# DPHY_TX0 register map
Vendor: Texas Instruments
Registers are 32-bit, read-write, reset 0x0 unless marked. A register's access mark holds for its fields unless they carry their own. Offsets are as the file gives them; [hi:lo] are bit positions; {n}, {i} and the like mark numbered series; <NAME> marks a mode.

## DPHY_TX0 (part 2 of 2)
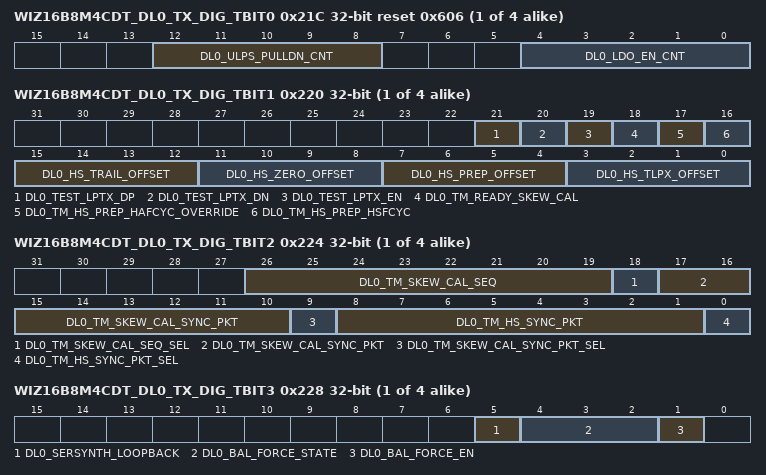
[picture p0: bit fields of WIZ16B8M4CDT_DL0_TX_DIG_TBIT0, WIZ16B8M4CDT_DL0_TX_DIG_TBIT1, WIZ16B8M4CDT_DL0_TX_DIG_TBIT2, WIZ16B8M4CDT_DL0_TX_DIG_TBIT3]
{0x21C+0x100*i} WIZ16B8M4CDT_DL{i}_TX_DIG_TBIT0 reset 0x606 (i=0..3)
  [12:8] DL{i}_ULPS_PULLDN_CNT — After enabling LDO, ulps_pulldn will go to 0 after these many uS
  [4:0] DL{i}_LDO_EN_CNT — Once the analog's power down signal is de asserted, LDO will be enabled after these many uS
{0x220+0x100*i} WIZ16B8M4CDT_DL{i}_TX_DIG_TBIT1 (i=0..3)
  [21] DL{i}_TEST_LPTX_DP — send 0 to LP TX Dn in HS mode
  [20] DL{i}_TEST_LPTX_DN — send 0 to LP TX Dp in HS mode
  [19] DL{i}_TEST_LPTX_EN — give output for LPTX from dig logic for HS entry LP sequence
  [18] DL{i}_TM_READY_SKEW_CAL — Assert o_TxReadyHS during skew caliberation pattern transmission.
  [17] DL{i}_TM_HS_PREP_HAFCYC_OVERRIDE — HS Prepare extra half cycle offset is controlled by digital logic
  [16] DL{i}_TM_HS_PREP_HSFCYC — If bit 17 == 1 Sets HS Prepare extra offset to 0 half cycle
  [15:12] DL{i}_HS_TRAIL_OFFSET — Sets HS-TRAIL Offset to 0
  [11:8] DL{i}_HS_ZERO_OFFSET — Sets HS-ZERO offset to 0
  [7:4] DL{i}_HS_PREP_OFFSET — Sets HS-PREPARE offset to 0
  [3:0] DL{i}_HS_TLPX_OFFSET — Sets TLPX Offset to 0
{0x224+0x100*i} WIZ16B8M4CDT_DL{i}_TX_DIG_TBIT2 (i=0..3)
  [26:19] DL{i}_TM_SKEW_CAL_SEQ — desired skew calibration test sequence
  [18] DL{i}_TM_SKEW_CAL_SEQ_SEL — To send 'AA as skew calibration pattern
  [17:10] DL{i}_TM_SKEW_CAL_SYNC_PKT — desired skew calibration test sync packet
  [9] DL{i}_TM_SKEW_CAL_SYNC_PKT_SEL — To send 'FF as Skew calibration sync packet
  [8:1] DL{i}_TM_HS_SYNC_PKT — desired HS test sync packet
  [0] DL{i}_TM_HS_SYNC_PKT_SEL — To send 'B8 as HS sync packet
{0x228+0x100*i} WIZ16B8M4CDT_DL{i}_TX_DIG_TBIT3 (i=0..3)
  [5] DL{i}_SERSYNTH_LOOPBACK — De-serialiser will take input from sampler
  [4:2] DL{i}_BAL_FORCE_STATE — Force the SYNC packet detection logic into below states if <1> is '1', SYNC_DONE state
  [1] DL{i}_BAL_FORCE_EN — SYNC packet detection FSM in serialiser in BIST mode will work as per logic
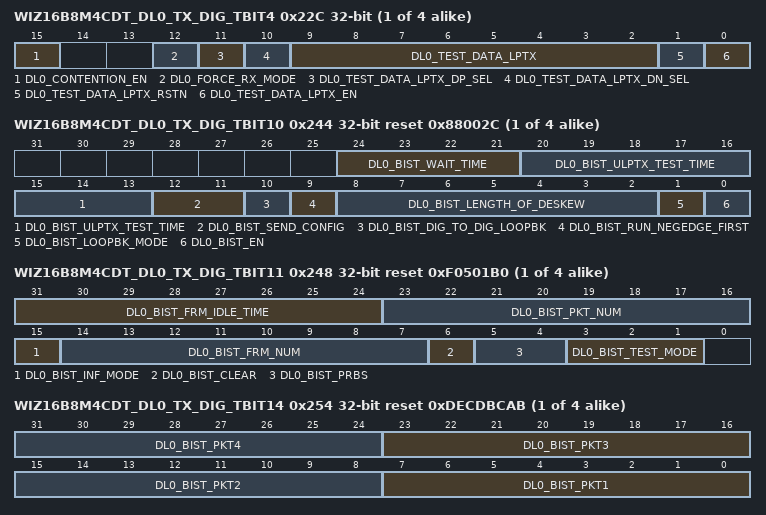
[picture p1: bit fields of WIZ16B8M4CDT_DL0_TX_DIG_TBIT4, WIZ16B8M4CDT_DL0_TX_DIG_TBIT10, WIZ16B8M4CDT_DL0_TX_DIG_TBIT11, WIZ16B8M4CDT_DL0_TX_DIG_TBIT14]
{0x22C+0x100*i} WIZ16B8M4CDT_DL{i}_TX_DIG_TBIT4 (i=0..3)
  [15] DL{i}_CONTENTION_EN — Contention detector logic is enabled
  [12] DL{i}_FORCE_RX_MODE — Force LPRX into RX mode
  [11] DL{i}_TEST_DATA_LPTX_DP_SEL — Normal_ LPTX DP_B from logic for LPDT
  [10] DL{i}_TEST_DATA_LPTX_DN_SEL — Normal_ LPTX DN_B from logic for LPDT
  [9:2] DL{i}_TEST_DATA_LPTX — LPTX test data
  [1] DL{i}_TEST_DATA_LPTX_RSTN — LP test data logic is RESET
  [0] DL{i}_TEST_DATA_LPTX_EN — LP test data logic DISABLED
{0x230+0x100*i} WIZ16B8M4CDT_DL{i}_TX_DIG_TBIT5 access not given reset not defined (i=0..3)
{0x234+0x100*i} WIZ16B8M4CDT_DL{i}_TX_DIG_TBIT6 access not given reset not defined (i=0..3)
{0x238+0x100*i} WIZ16B8M4CDT_DL{i}_TX_DIG_TBIT7 access not given reset not defined (i=0..3)
{0x23C+0x100*i} WIZ16B8M4CDT_DL{i}_TX_DIG_TBIT8 access not given reset not defined (i=0..3)
{0x240+0x100*i} WIZ16B8M4CDT_DL{i}_TX_DIG_TBIT9 access not given reset not defined (i=0..3)
{0x244+0x100*i} WIZ16B8M4CDT_DL{i}_TX_DIG_TBIT10 reset 0x88002C (i=0..3)
  [24:21] DL{i}_BIST_WAIT_TIME — BIST wait time between posedge run and negedge run of sampler clock
  [20:13] DL{i}_BIST_ULPTX_TEST_TIME — While testing ULPTX, LP00 will be maintained on DPDN for this many number of byte clock cycles
  [12:11] DL{i}_BIST_SEND_CONFIG — Option of configuring what to send in BIST mose. To send both deskew and HS data
  [10] DL{i}_BIST_DIG_TO_DIG_LOOPBK — main digital to pattern checker loopback enabled
  [9] DL{i}_BIST_RUN_NEGEDGE_FIRST — BIST will run with posedge of sampler clock first
  [8:2] DL{i}_BIST_LENGTH_OF_DESKEW — Length of deskew sequence In terms of us. By default 13us of deskew sequence will be transmitted
  [1] DL{i}_BIST_LOOPBK_MODE — loopback_mode bit, EXTERNAL_LOOPBACK
  [0] DL{i}_BIST_EN — BIST Disabled
{0x248+0x100*i} WIZ16B8M4CDT_DL{i}_TX_DIG_TBIT11 reset 0xF0501B0 (i=0..3)
  [31:24] DL{i}_BIST_FRM_IDLE_TIME — BIST_FRM_IDLE time is time between the frames
  [23:16] DL{i}_BIST_PKT_NUM — BIST_PAK_NUM is number of packets that are to be transmitted per frame
  [15] DL{i}_BIST_INF_MODE — run infinite BIST mode
  [14:7] DL{i}_BIST_FRM_NUM — BIST_FRM_NUM is number of frames to be transmitted
  [6] DL{i}_BIST_CLEAR — clear the bist
  [5:4] DL{i}_BIST_PRBS — BIST PRBS MODE 9
  [3:1] DL{i}_BIST_TEST_MODE — PRBS mode
{0x24C+0x100*i} WIZ16B8M4CDT_DL{i}_TX_DIG_TBIT12 reset 0x28 (i=0..3)
  [11:0] DL{i}_BIST_RUN_LENGTH — BIST_RUN_LENGTH
{0x250+0x100*i} WIZ16B8M4CDT_DL{i}_TX_DIG_TBIT13 reset 0xA (i=0..3)
  [7:0] DL{i}_BIST_IDLE_TIME — BIST_IDLE_TIME
{0x254+0x100*i} WIZ16B8M4CDT_DL{i}_TX_DIG_TBIT14 reset 0xDECDBCAB (i=0..3)
  [8n-1:8n-8] DL{i}_BIST_PKT{n} (n=1..4) — BIST_TEST_PAT{n}
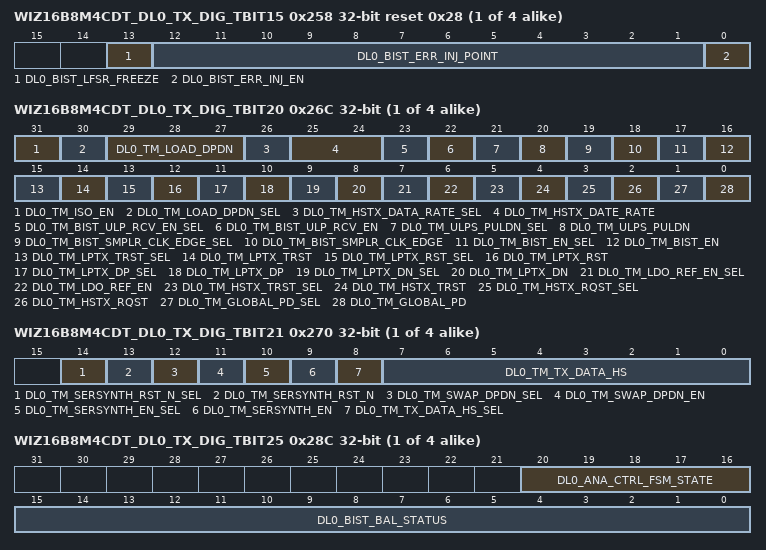
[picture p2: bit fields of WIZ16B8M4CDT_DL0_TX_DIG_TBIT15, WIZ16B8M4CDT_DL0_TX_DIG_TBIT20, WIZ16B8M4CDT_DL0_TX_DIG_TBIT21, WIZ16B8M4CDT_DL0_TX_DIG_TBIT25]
{0x258+0x100*i} WIZ16B8M4CDT_DL{i}_TX_DIG_TBIT15 reset 0x28 (i=0..3)
  [13] DL{i}_BIST_LFSR_FREEZE — Reset LFSR contents after every packet or frame
  [12:1] DL{i}_BIST_ERR_INJ_POINT — BIST_ERR_INJECT_POINT is where to inject the error in the packet
  [0] DL{i}_BIST_ERR_INJ_EN — Inject error in the BIST during the packet
{0x25C+0x100*i} WIZ16B8M4CDT_DL{i}_TX_DIG_TBIT16 access not given reset not defined (i=0..3)
{0x260+0x100*i} WIZ16B8M4CDT_DL{i}_TX_DIG_TBIT17 access not given reset not defined (i=0..3)
{0x264+0x100*i} WIZ16B8M4CDT_DL{i}_TX_DIG_TBIT18 access not given reset not defined (i=0..3)
{0x268+0x100*i} WIZ16B8M4CDT_DL{i}_TX_DIG_TBIT19 access not given reset not defined (i=0..3)
{0x26C+0x100*i} WIZ16B8M4CDT_DL{i}_TX_DIG_TBIT20 (i=0..3)
  [31] DL{i}_TM_ISO_EN — Enable isolation in test mode
  [30] DL{i}_TM_LOAD_DPDN_SEL — Take ana_dpdn_load from dig logic
  [29:27] DL{i}_TM_LOAD_DPDN — set ana_dpdn_load as per requirement in test mode
  [26] DL{i}_TM_HSTX_DATA_RATE_SEL — Take ana_hstx_datarate from dig logic
  [25:24] DL{i}_TM_HSTX_DATE_RATE — set ana_hstx_datarate as per requirement in test mode
  [23] DL{i}_TM_BIST_ULP_RCV_EN_SEL — Take ana_bist_ulps_rcv_en from dig logic
  [22] DL{i}_TM_BIST_ULP_RCV_EN — set ana_bist_ulps_rcv_en to 0
  [21] DL{i}_TM_ULPS_PULDN_SEL — Take ana_ulps_puldn from dig logic
  [20] DL{i}_TM_ULPS_PULDN — set ana_ulps_puldn to 0
  [19] DL{i}_TM_BIST_SMPLR_CLK_EDGE_SEL — Take ana_bist_smplr_clkedge from dig logic
  [18] DL{i}_TM_BIST_SMPLR_CLK_EDGE — set ana_bist_smplr_clkedge to posedge
  [17] DL{i}_TM_BIST_EN_SEL — Take ana_bist_en from dig logic
  [16] DL{i}_TM_BIST_EN — set ana_bist_en to 0
  [15] DL{i}_TM_LPTX_TRST_SEL — Take ana_lptx_trst from dig logic
  [14] DL{i}_TM_LPTX_TRST — set ana_lptx_trst to 0
  [13] DL{i}_TM_LPTX_RST_SEL — Take ana_lptx_rst from dig logic
  [12] DL{i}_TM_LPTX_RST — set ana_lptx_rst to 0
  [11] DL{i}_TM_LPTX_DP_SEL — give output for LPTX DP from dig logic
  [10] DL{i}_TM_LPTX_DP — send 0 to LP TX Dp
  [9] DL{i}_TM_LPTX_DN_SEL — give output for LPTX DN from dig logic
  [8] DL{i}_TM_LPTX_DN — send 0 to LP TX Dn
  [7] DL{i}_TM_LDO_REF_EN_SEL — Take ana_ldo_ref_en from dig logic
  [6] DL{i}_TM_LDO_REF_EN — set ana_ldo_ref_en to 0
  [5] DL{i}_TM_HSTX_TRST_SEL — Take ana_hstx_trst from dig logic
  [4] DL{i}_TM_HSTX_TRST — set ana_hstx_trst to 0
  [3] DL{i}_TM_HSTX_RQST_SEL — Take ana_hstx_rqst from dig logic
  [2] DL{i}_TM_HSTX_RQST — set ana_hstx_rqst to 0
  [1] DL{i}_TM_GLOBAL_PD_SEL — Take ana_global_pd from dig logic
  [0] DL{i}_TM_GLOBAL_PD — set ana_global_pd to 0 (powered up)
{0x270+0x100*i} WIZ16B8M4CDT_DL{i}_TX_DIG_TBIT21 (i=0..3)
  [14] DL{i}_TM_SERSYNTH_RST_N_SEL — Take sersynth_rst_n from dig logic
  [13] DL{i}_TM_SERSYNTH_RST_N — Set sersynth_rst_n to 1
  [12] DL{i}_TM_SWAP_DPDN_SEL — Take swapdp_dn from dig logic
  [11] DL{i}_TM_SWAP_DPDN_EN — Set swap_dpdn to 1
  [10] DL{i}_TM_SERSYNTH_EN_SEL — Take sersynth_en from dig logic
  [9] DL{i}_TM_SERSYNTH_EN — set sersynth_en to 1
  [8] DL{i}_TM_TX_DATA_HS_SEL — sends single test byte to sersynth, which is in <7:0>
  [7:0] DL{i}_TM_TX_DATA_HS — Test byte that can be sent constantly to sersynth. This is validated by bit <8> of this reg
{0x274+0x100*i} WIZ16B8M4CDT_DL{i}_TX_DIG_TBIT22 (i=0..3)
  [31:0] DL{i}_DIG_TBIT22 — spare
{0x278+0x100*i} WIZ16B8M4CDT_DL{i}_TX_DIG_TBIT23 access not given reset not defined (i=0..3)
{0x27C+0x100*i} WIZ16B8M4CDT_DL{i}_TX_DIG_TBIT24 access not given reset not defined (i=0..3)
{0x280+0x100*i} WIZ16B8M4CDT_DL{i}_TX_ANA_TBIT5 ro (i=0..3)
  [31:0] DL{i}_ANA_TBIT5 — Analog Test register 5
{0x28C+0x100*i} WIZ16B8M4CDT_DL{i}_TX_DIG_TBIT25 ro (i=0..3)
  [20:16] DL{i}_ANA_CTRL_FSM_STATE — FSM state readout for ana_ctrl
  [15:0] DL{i}_BIST_BAL_STATUS — BAL logic status read
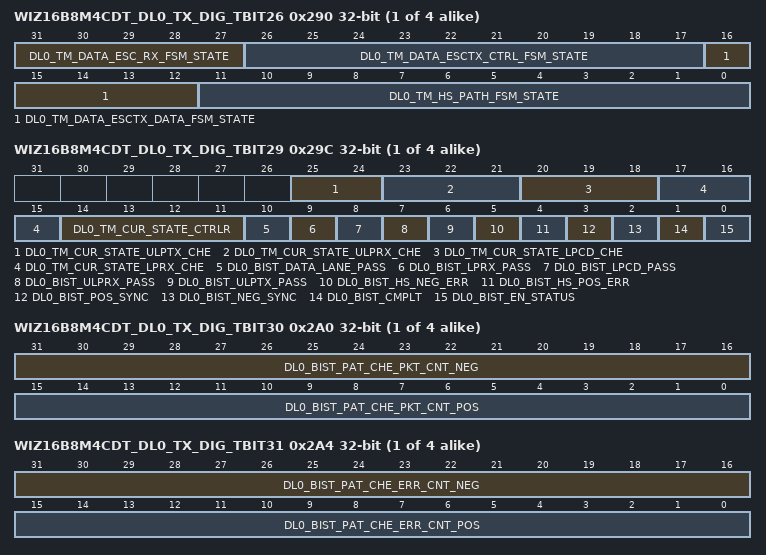
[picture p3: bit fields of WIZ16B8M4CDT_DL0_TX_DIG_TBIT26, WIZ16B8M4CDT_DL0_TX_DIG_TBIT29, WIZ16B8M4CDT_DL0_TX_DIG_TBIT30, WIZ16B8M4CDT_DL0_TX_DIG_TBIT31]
{0x290+0x100*i} WIZ16B8M4CDT_DL{i}_TX_DIG_TBIT26 ro (i=0..3)
  [31:27] DL{i}_TM_DATA_ESC_RX_FSM_STATE — FSM state readout for esc rx path
  [26:17] DL{i}_TM_DATA_ESCTX_CTRL_FSM_STATE — fsm state for escape tx control path
  [16:12] DL{i}_TM_DATA_ESCTX_DATA_FSM_STATE — fsm state for escape tx data path
  [11:0] DL{i}_TM_HS_PATH_FSM_STATE — FSM state readout for hs path fsm
{0x298+0x100*i} WIZ16B8M4CDT_DL{i}_TX_DIG_TBIT28 ro (i=0..3)
  [15:8] DL{i}_TM_ANA_COMP_OUTS — Analog components outputs
{0x29C+0x100*i} WIZ16B8M4CDT_DL{i}_TX_DIG_TBIT29 ro (i=0..3)
  [25:24] DL{i}_TM_CUR_STATE_ULPTX_CHE — Current state of the ULPTX checker FSM
  [23:21] DL{i}_TM_CUR_STATE_ULPRX_CHE — Current state of the ULPRX checker FSM
  [20:18] DL{i}_TM_CUR_STATE_LPCD_CHE — Current state of the LPCD checker FSM
  [17:15] DL{i}_TM_CUR_STATE_LPRX_CHE — Current state of the LPRX checker FSM
  [14:11] DL{i}_TM_CUR_STATE_CTRLR — Current state of the Control FSM
  [10] DL{i}_BIST_DATA_LANE_PASS — Data lane has passed BIST completely
  [9] DL{i}_BIST_LPRX_PASS — LPRX BIST pass
  [8] DL{i}_BIST_LPCD_PASS — LPCD BIST Passed
  [7] DL{i}_BIST_ULPRX_PASS — ULPRX BIST passed
  [6] DL{i}_BIST_ULPTX_PASS — ULPTX BIST passed
  [5] DL{i}_BIST_HS_NEG_ERR — HS Bist error detected with negedge of sampler clock
  [4] DL{i}_BIST_HS_POS_ERR — HS Bist error detected with posedge of sampler clock
  [3] DL{i}_BIST_POS_SYNC — Pattern checker in negedge run have synced with pattern generator
  [2] DL{i}_BIST_NEG_SYNC — Pattern checker in posedge run have synced with pattern generator
  [1] DL{i}_BIST_CMPLT — BIST is completed
  [0] DL{i}_BIST_EN_STATUS — BIST Controller is enabled
{0x2A0+0x100*i} WIZ16B8M4CDT_DL{i}_TX_DIG_TBIT30 ro (i=0..3)
  [31:16] DL{i}_BIST_PAT_CHE_PKT_CNT_NEG — pattern checker packet count with negedge run of sampler clock
  [15:0] DL{i}_BIST_PAT_CHE_PKT_CNT_POS — pattern checker packet count with posedge run of sampler clock
{0x2A4+0x100*i} WIZ16B8M4CDT_DL{i}_TX_DIG_TBIT31 ro (i=0..3)
  [31:16] DL{i}_BIST_PAT_CHE_ERR_CNT_NEG — pattern checker error count with negedge run of sampler clock
  [15:0] DL{i}_BIST_PAT_CHE_ERR_CNT_POS — pattern checker error count with posedge run of sampler clock
{0x2A8+0x100*i} WIZ16B8M4CDT_DL{i}_TX_DIG_TBIT32 access not given reset not defined (i=0..3)
{0x2AC+0x100*i} WIZ16B8M4CDT_DL{i}_TX_DIG_TBIT33 access not given reset not defined (i=0..3)
{0x2B0+0x100*i} WIZ16B8M4CDT_DL{i}_TX_DIG_TBIT34 access not given reset not defined (i=0..3)
{0x2B4+0x100*i} WIZ16B8M4CDT_DL{i}_TX_DIG_TBIT35 access not given reset not defined (i=0..3)
{0x2B8+0x100*i} WIZ16B8M4CDT_DL{i}_TX_DIG_TBIT36 access not given reset not defined (i=0..3)
{0x300+4i} WIZ16B8M4CDT_DL1_TX_ANA_TBIT{i} (i=0..4)
  [31:0] DL1_ANA_TBIT{i} — Analog Test register {i}
{0x400+4i} WIZ16B8M4CDT_DL2_TX_ANA_TBIT{i} (i=0..4)
  [31:0] DL2_ANA_TBIT{i} — Analog Test register {i}
{0x500+4i} WIZ16B8M4CDT_DL3_TX_ANA_TBIT{i} (i=0..4)
  [31:0] DL3_ANA_TBIT{i} — Analog Test register {i}
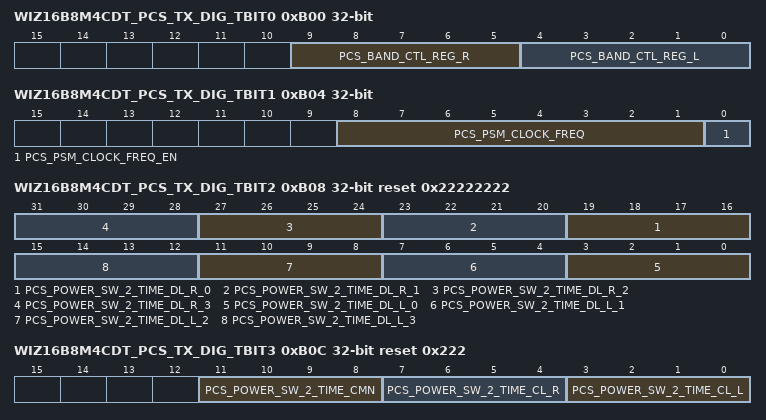
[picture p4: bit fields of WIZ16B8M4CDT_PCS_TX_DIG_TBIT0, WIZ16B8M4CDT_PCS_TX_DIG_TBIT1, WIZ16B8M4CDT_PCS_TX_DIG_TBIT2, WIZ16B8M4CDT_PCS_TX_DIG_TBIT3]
0xB00 WIZ16B8M4CDT_PCS_TX_DIG_TBIT0
  [9:5] PCS_BAND_CTL_REG_R — Data Rate 80_100 MHz
  [4:0] PCS_BAND_CTL_REG_L — Data Rate 80_100 MHz
0xB04 WIZ16B8M4CDT_PCS_TX_DIG_TBIT1
  [8:1] PCS_PSM_CLOCK_FREQ — psm_clock freq value
  [0] PCS_PSM_CLOCK_FREQ_EN — take psm_clock_freq from tbit
0xB08 WIZ16B8M4CDT_PCS_TX_DIG_TBIT2 reset 0x22222222
  [4n+19:4n+16] PCS_POWER_SW_2_TIME_DL_R_{n} (n=0..3) — power_sw_2_time_dl_r_{n}
  [4n+3:4n] PCS_POWER_SW_2_TIME_DL_L_{n} (n=0..3) — power_sw_2_time_dl_l_{n}
0xB0C WIZ16B8M4CDT_PCS_TX_DIG_TBIT3 reset 0x222
  [11:8] PCS_POWER_SW_2_TIME_CMN — power_sw_2_time_cmn
  [7:4] PCS_POWER_SW_2_TIME_CL_R — power_sw_2_time_cl_r
  [3:0] PCS_POWER_SW_2_TIME_CL_L — power_sw_2_time_cl_l
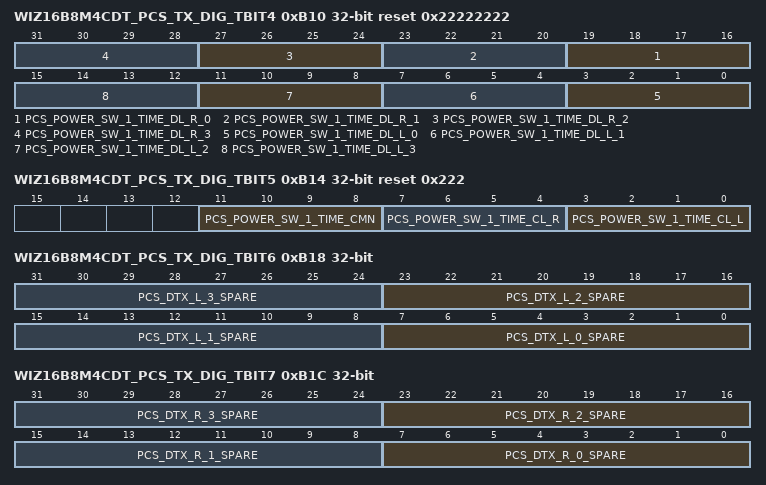
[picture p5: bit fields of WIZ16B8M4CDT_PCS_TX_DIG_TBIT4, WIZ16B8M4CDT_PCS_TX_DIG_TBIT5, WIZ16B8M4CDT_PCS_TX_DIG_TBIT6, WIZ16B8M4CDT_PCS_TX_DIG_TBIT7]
0xB10 WIZ16B8M4CDT_PCS_TX_DIG_TBIT4 reset 0x22222222
  [4n+19:4n+16] PCS_POWER_SW_1_TIME_DL_R_{n} (n=0..3) — power_sw_1_time_dl_r_{n}
  [4n+3:4n] PCS_POWER_SW_1_TIME_DL_L_{n} (n=0..3) — power_sw_1_time_dl_l_{n}
0xB14 WIZ16B8M4CDT_PCS_TX_DIG_TBIT5 reset 0x222
  [11:8] PCS_POWER_SW_1_TIME_CMN — power_sw_1_time_cmn
  [7:4] PCS_POWER_SW_1_TIME_CL_R — power_sw_1_time_cl_r
  [3:0] PCS_POWER_SW_1_TIME_CL_L — power_sw_1_time_cl_l
0xB18 WIZ16B8M4CDT_PCS_TX_DIG_TBIT6
  [8n+7:8n] PCS_DTX_L_{n}_SPARE (n=0..3) — dtx_l_{n} spare port
0xB1C WIZ16B8M4CDT_PCS_TX_DIG_TBIT7
  [8n+7:8n] PCS_DTX_R_{n}_SPARE (n=0..3) — dtx_r_{n} spare port
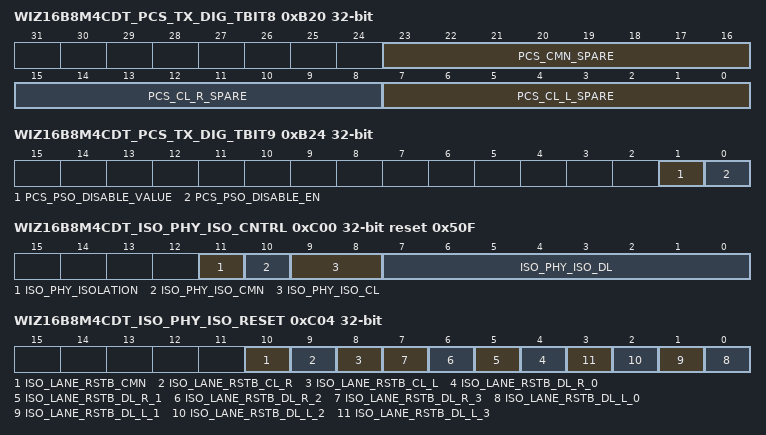
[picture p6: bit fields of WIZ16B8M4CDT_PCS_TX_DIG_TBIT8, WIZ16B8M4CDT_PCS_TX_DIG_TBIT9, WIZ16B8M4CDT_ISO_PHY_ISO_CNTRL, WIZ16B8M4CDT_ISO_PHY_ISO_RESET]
0xB20 WIZ16B8M4CDT_PCS_TX_DIG_TBIT8
  [23:16] PCS_CMN_SPARE — cmn spare port
  [15:8] PCS_CL_R_SPARE — cl_r spare port
  [7:0] PCS_CL_L_SPARE — cl_l spare port
0xB24 WIZ16B8M4CDT_PCS_TX_DIG_TBIT9
  [1] PCS_PSO_DISABLE_VALUE — pso_disbale value
  [0] PCS_PSO_DISABLE_EN — take pso_diable from tbit
0xB28 WIZ16B8M4CDT_PCS_TX_DIG_TBIT10
  [31:0] PCS_DIG_TBIT10 — Digital Test Register Extra 4
0xC00 WIZ16B8M4CDT_ISO_PHY_ISO_CNTRL reset 0x50F
  [11] ISO_PHY_ISOLATION — when set enables phy_isolation
  [10] ISO_PHY_ISO_CMN — This bit enables the Isolation on Common Lane
  [9:8] ISO_PHY_ISO_CL — Bit 1: Setting a value 1 isolates the Right Clock Lane
  [7:0] ISO_PHY_ISO_DL — Bit 7: Setting a value 1 isolates the Data Lane 3 on Right Link
0xC04 WIZ16B8M4CDT_ISO_PHY_ISO_RESET
  [10] ISO_LANE_RSTB_CMN — Drives the Lane Reset for Common lane_rstb_cmn
  [9] ISO_LANE_RSTB_CL_R — Drives the Right Clock Lane Reset lane_rstb_cl_l
  [8] ISO_LANE_RSTB_CL_L — Drives the Left Clock Lane Reset lane_rstb_cl_l
  [n+4] ISO_LANE_RSTB_DL_R_{n} (n=0..3) — Drives the Data Lane {n} Right Link Reset lane_rstb_dl_{n+4}
  [n] ISO_LANE_RSTB_DL_L_{n} (n=0..3) — Drives the Data Lane {n} Left Link Reset lane_rstb_dl_{n}
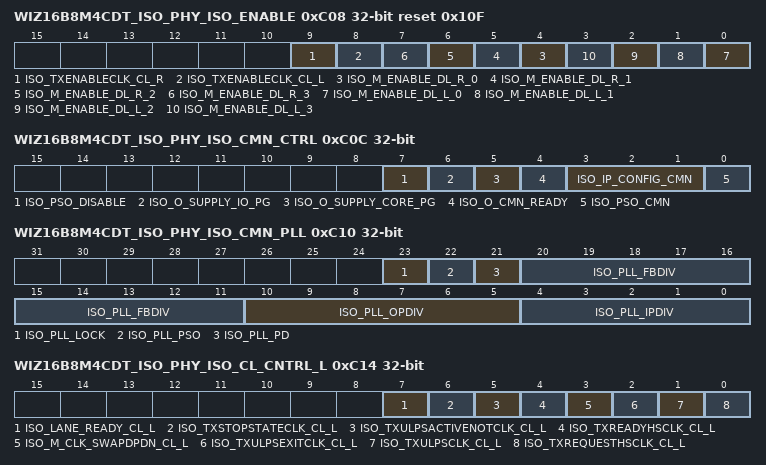
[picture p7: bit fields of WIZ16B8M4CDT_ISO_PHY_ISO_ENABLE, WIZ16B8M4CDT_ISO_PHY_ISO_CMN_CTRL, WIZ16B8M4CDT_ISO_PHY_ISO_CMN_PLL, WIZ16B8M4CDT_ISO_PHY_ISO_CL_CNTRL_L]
0xC08 WIZ16B8M4CDT_ISO_PHY_ISO_ENABLE reset 0x10F
  [9] ISO_TXENABLECLK_CL_R — Drives to enable the right clock lane TxEnableClk_clk_r
  [8] ISO_TXENABLECLK_CL_L — Drives to enable the left clock lane TxEnableClk_clk_l
  [n+4] ISO_M_ENABLE_DL_R_{n} (n=0..3) — Enables the Data Lane {n} Right Link M_Enable_dl_{n+4}
  [n] ISO_M_ENABLE_DL_L_{n} (n=0..3) — Enables the Data Lane {n} Left Link M_Enable_dl_{n}
0xC0C WIZ16B8M4CDT_ISO_PHY_ISO_CMN_CTRL access per field
  [7] ISO_PSO_DISABLE rw — Drives pso_disable
  [6] ISO_O_SUPPLY_IO_PG ro — I/O supply power is good o_supply_io_pg
  [5] ISO_O_SUPPLY_CORE_PG ro — Core Supply Power is good o_supply_core_pg
  [4] ISO_O_CMN_READY ro — Common ready Indicator o_cmn_ready
  [3:1] ISO_IP_CONFIG_CMN rw — Drives the IP configuration to decide which clock lane acts as the master lane to all clock lanes ip_config_cmn
  [0] ISO_PSO_CMN rw — Drives the power shut off for the Common pso_cmn
0xC10 WIZ16B8M4CDT_ISO_PHY_ISO_CMN_PLL access per field
  [23] ISO_PLL_LOCK ro — A value 1 indicates the PLL clock is locked to the reference clock (pll_lock)
  [22] ISO_PLL_PSO rw — Connected to pll_pso which are Reserved and reserved for future use
  [21] ISO_PLL_PD rw — Connected to pll_pd which are Reserved and reserved for future use
  [20:11] ISO_PLL_FBDIV rw — Drives the PLL feedback divider value {pll_fbdiv[9:0]}
  [10:5] ISO_PLL_OPDIV rw — Drives the PLL output divider value {pll_opdiv[5:0]} [On APB clock domain]
  [4:0] ISO_PLL_IPDIV rw — Drives the PLL input divider value {pll_ipdiv[4:0]}
0xC14 WIZ16B8M4CDT_ISO_PHY_ISO_CL_CNTRL_L access per field
  [7] ISO_LANE_READY_CL_L ro — clock lane ready
  [6] ISO_TXSTOPSTATECLK_CL_L ro — Driven high when the clock lane is in stop state TxStopStateClk_cl_l
  [5] ISO_TXULPSACTIVENOTCLK_CL_L ro — Driven high when the clock lane is in ULPS active state TxULPSActiveNotClk_clk_l
  [4] ISO_TXREADYHSCLK_CL_L ro — Stores the High Speed Clock Transmission Ready TxReadyHSClk_clk_l
  [3] ISO_M_CLK_SWAPDPDN_CL_L rw — Drives the value to enable the Swap of DP and DN signals inside the clock lane M_Clk_SwapDpDn_clk_l
  [2] ISO_TXULPSEXITCLK_CL_L rw — Drives to initiate exit of ULPS TxULPSExitClk_clk_l
  [1] ISO_TXULPSCLK_CL_L rw — Drives to initiate entry to ULPS TxULPSClk _clk_l
  [0] ISO_TXREQUESTHSCLK_CL_L rw — Drives the High Speed Clock Transmission Request TxRequestHSClk_clk_l
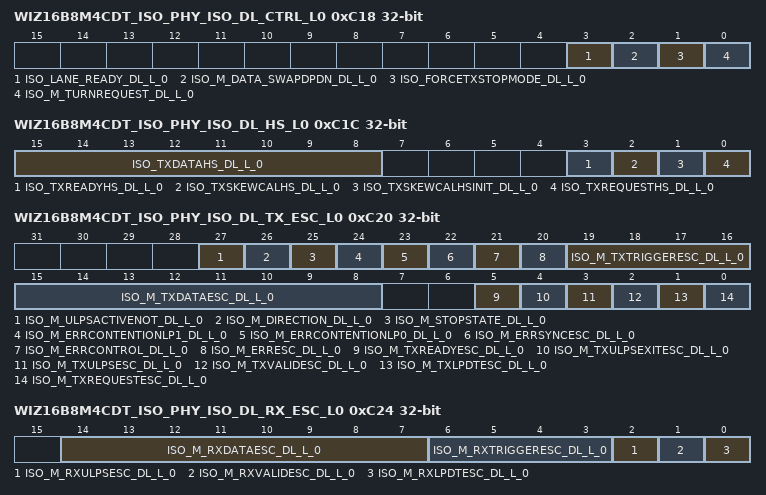
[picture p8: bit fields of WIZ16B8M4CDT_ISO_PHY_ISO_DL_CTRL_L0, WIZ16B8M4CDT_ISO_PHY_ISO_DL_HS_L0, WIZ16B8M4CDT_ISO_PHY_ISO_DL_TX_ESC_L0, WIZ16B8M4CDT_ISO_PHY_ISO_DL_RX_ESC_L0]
0xC18 WIZ16B8M4CDT_ISO_PHY_ISO_DL_CTRL_L0 access per field
  [3] ISO_LANE_READY_DL_L_0 ro — High Speed data lane ready lane_ready_dl_l_0
  [2] ISO_M_DATA_SWAPDPDN_DL_L_0 rw — Swaps the tx_p and tx_m differential pins M_Data_SwapDpDn_dl_l_0
  [1] ISO_FORCETXSTOPMODE_DL_L_0 rw — Drives the lane forcing into stop state ForceTxStopMode_dl_l_0
  [0] ISO_M_TURNREQUEST_DL_L_0 rw — Drives the Turnaround request M_TurnRequest_dl_l_0
0xC1C WIZ16B8M4CDT_ISO_PHY_ISO_DL_HS_L0 access per field
  [15:8] ISO_TXDATAHS_DL_L_0 rw — Drives the high speed transmission data TxDataHS_dl_l_0[7:0]
  [3] ISO_TXREADYHS_DL_L_0 ro — Stores the high speed data transmission ready TxReadyHS_dl_l_0
  [2] ISO_TXSKEWCALHS_DL_L_0 rw — Drives transmission skew calibration periodic TxSkewCalHS_dl_l_0
  [1] ISO_TXSKEWCALHSINIT_DL_L_0 rw — Drives to run the initial skew calibration TxSkewCalHSInit_dl_l_0
  [0] ISO_TXREQUESTHS_DL_L_0 rw — Drives the High Speed Data Transmission Request TxRequestHS_dl_l_0
0xC20 WIZ16B8M4CDT_ISO_PHY_ISO_DL_TX_ESC_L0 access per field
  [27] ISO_M_ULPSACTIVENOT_DL_L_0 ro — Lane ULPS Active state M_ULPSActiveNot_dl_l_0
  [26] ISO_M_DIRECTION_DL_L_0 ro — Lane transmit / receive direction M_Direction_dl_l_0
  [25] ISO_M_STOPSTATE_DL_L_0 ro — Lane Stop State M_StopState_dl_l_0
  [24] ISO_M_ERRCONTENTIONLP1_DL_L_0 ro — LP1 contention Error M_ErrContentionLP1_dl_l_0
  [23] ISO_M_ERRCONTENTIONLP0_DL_L_0 ro — LP1 contention Error M_ErrContentionLP0_dl_l_0
  [22] ISO_M_ERRSYNCESC_DL_L_0 ro — Low power data transmission sync error M_ErrSyncEsc_dl_l_0
  [21] ISO_M_ERRCONTROL_DL_L_0 ro — Control Error M_ErrControl_dl_l_0
  [20] ISO_M_ERRESC_DL_L_0 ro — Escape Entry Error M_ErrEsc_dl_l_0
  [19:16] ISO_M_TXTRIGGERESC_DL_L_0 rw — Transmit escape mode trigger M_TxTriggerEsc_dl_l_0[3:0]
  [15:8] ISO_M_TXDATAESC_DL_L_0 rw — Transmit escape mode low power transmit data M_TxDataEsc_dl_l_0[7:0]
  [5] ISO_M_TXREADYESC_DL_L_0 ro — Transmit escape mode low power transmit data ready M_TxReadyEsc_dl_l_0
  [4] ISO_M_TXULPSEXITESC_DL_L_0 rw — Initiate exit of ULPS M_TxULPSExitEsc_dl_l_0
  [3] ISO_M_TXULPSESC_DL_L_0 rw — Transmit escape mode ultra low power state M_TxULPSEsc_dl_l_0
  [2] ISO_M_TXVALIDESC_DL_L_0 rw — Transmit escape mode low power transmit data valid M_TxValidEsc_dl_l_0
  [1] ISO_M_TXLPDTESC_DL_L_0 rw — Transmit escape mode low power data M_TxLPDTEsc_dl_l_0
  [0] ISO_M_TXREQUESTESC_DL_L_0 rw — Transmit escape mode request M_TxRequestEsc_dl_l_0
0xC24 WIZ16B8M4CDT_ISO_PHY_ISO_DL_RX_ESC_L0 ro
  [14:7] ISO_M_RXDATAESC_DL_L_0 — Receive escape mode low power receive data M_RxDataEsc_dl_l_0[7:0]
  [6:3] ISO_M_RXTRIGGERESC_DL_L_0 — Receive escape mode low power trigger state M_RxTriggerEsc_dl_l_0[3:0]
  [2] ISO_M_RXULPSESC_DL_L_0 — Receive escape mode low power ultra low power state M_RxULPSEsc_dl_l_0
  [1] ISO_M_RXVALIDESC_DL_L_0 — Receive escape mode low power receive data M_RxValidEsc_dl_l_0
  [0] ISO_M_RXLPDTESC_DL_L_0 — Receive escape mode low power data M_RxLPDTEsc_dl_l_0
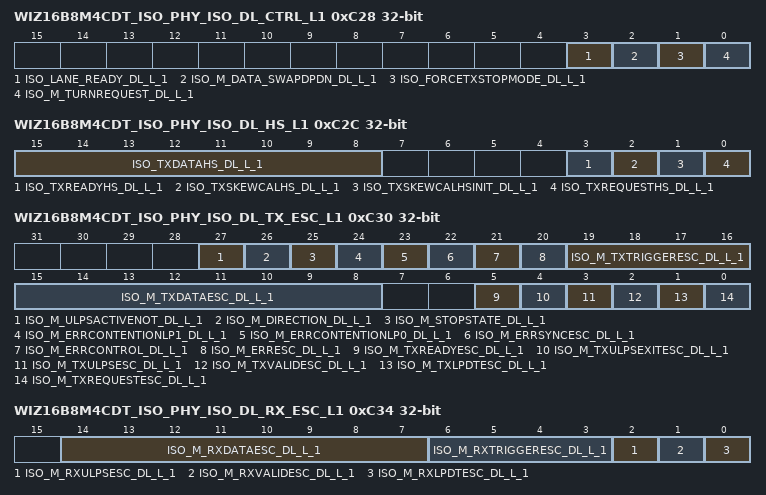
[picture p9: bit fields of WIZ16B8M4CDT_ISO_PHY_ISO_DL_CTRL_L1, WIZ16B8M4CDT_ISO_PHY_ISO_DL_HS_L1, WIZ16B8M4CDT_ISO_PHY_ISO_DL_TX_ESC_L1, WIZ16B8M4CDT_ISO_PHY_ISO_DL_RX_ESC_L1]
0xC28 WIZ16B8M4CDT_ISO_PHY_ISO_DL_CTRL_L1 access per field
  [3] ISO_LANE_READY_DL_L_1 ro — High Speed data lane ready lane_ready_dl_l_1
  [2] ISO_M_DATA_SWAPDPDN_DL_L_1 rw — Swaps the tx_p and tx_m differential pins M_Data_SwapDpDn_dl_l_1
  [1] ISO_FORCETXSTOPMODE_DL_L_1 rw — Drives the lane forcing into stop state ForceTxStopMode_dl_l_1
  [0] ISO_M_TURNREQUEST_DL_L_1 rw — Drives the Turnaround request M_TurnRequest_dl_l_1
0xC2C WIZ16B8M4CDT_ISO_PHY_ISO_DL_HS_L1 access per field
  [15:8] ISO_TXDATAHS_DL_L_1 rw — Drives the high speed transmission data TxDataHS_dl_l_1[7:0]
  [3] ISO_TXREADYHS_DL_L_1 ro — Stores the high speed data transmission ready TxReadyHS_dl_l_1
  [2] ISO_TXSKEWCALHS_DL_L_1 rw — Drives transmission skew calibration periodic TxSkewCalHS_dl_l_1
  [1] ISO_TXSKEWCALHSINIT_DL_L_1 rw — Drives to run the initial skew calibration TxSkewCalHSInit_dl_l_1
  [0] ISO_TXREQUESTHS_DL_L_1 rw — Drives the High Speed Data Transmission Request TxRequestHS_dl_l_1
0xC30 WIZ16B8M4CDT_ISO_PHY_ISO_DL_TX_ESC_L1 access per field
  [27] ISO_M_ULPSACTIVENOT_DL_L_1 ro — Lane ULPS Active state M_ULPSActiveNot_dl_l_1
  [26] ISO_M_DIRECTION_DL_L_1 ro — Lane transmit / receive direction M_Direction_dl_l_1
  [25] ISO_M_STOPSTATE_DL_L_1 ro — Lane Stop State M_StopState_dl_l_1
  [24] ISO_M_ERRCONTENTIONLP1_DL_L_1 ro — LP1 contention Error M_ErrContentionLP1_dl_l_1
  [23] ISO_M_ERRCONTENTIONLP0_DL_L_1 ro — LP1 contention Error M_ErrContentionLP0_dl_l_1
  [22] ISO_M_ERRSYNCESC_DL_L_1 ro — Low power data transmission sync error M_ErrSyncEsc_dl_l_1
  [21] ISO_M_ERRCONTROL_DL_L_1 ro — Control Error M_ErrControl_dl_l_1
  [20] ISO_M_ERRESC_DL_L_1 ro — Escape Entry Error M_ErrEsc_dl_l_1
  [19:16] ISO_M_TXTRIGGERESC_DL_L_1 rw — Transmit escape mode trigger M_TxTriggerEsc_dl_l_1[3:0]
  [15:8] ISO_M_TXDATAESC_DL_L_1 rw — Transmit escape mode low power transmit data M_TxDataEsc_dl_l_1[7:0]
  [5] ISO_M_TXREADYESC_DL_L_1 ro — Transmit escape mode low power transmit data ready M_TxReadyEsc_dl_l_1
  [4] ISO_M_TXULPSEXITESC_DL_L_1 rw — Initiate exit of ULPS M_TxULPSExitEsc_dl_l_1
  [3] ISO_M_TXULPSESC_DL_L_1 rw — Transmit escape mode ultra low power state M_TxULPSEsc_dl_l_1
  [2] ISO_M_TXVALIDESC_DL_L_1 rw — Transmit escape mode low power transmit data valid M_TxValidEsc_dl_l_1
  [1] ISO_M_TXLPDTESC_DL_L_1 rw — Transmit escape mode low power data M_TxLPDTEsc_dl_l_1
  [0] ISO_M_TXREQUESTESC_DL_L_1 rw — Transmit escape mode request M_TxRequestEsc_dl_l_1
0xC34 WIZ16B8M4CDT_ISO_PHY_ISO_DL_RX_ESC_L1 ro
  [14:7] ISO_M_RXDATAESC_DL_L_1 — Receive escape mode low power receive data M_RxDataEsc_dl_l_1[7:0]
  [6:3] ISO_M_RXTRIGGERESC_DL_L_1 — Receive escape mode low power trigger state M_RxTriggerEsc_dl_l_1[3:0]
  [2] ISO_M_RXULPSESC_DL_L_1 — Receive escape mode low power ultra low power state M_RxULPSEsc_dl_l_1
  [1] ISO_M_RXVALIDESC_DL_L_1 — Receive escape mode low power receive data M_RxValidEsc_dl_l_1
  [0] ISO_M_RXLPDTESC_DL_L_1 — Receive escape mode low power data M_RxLPDTEsc_dl_l_1
0xC38 WIZ16B8M4CDT_ISO_PHY_ISO_SPARE_1 ro
  [31:0] ISO_SPARE — Spare register
0xC3C WIZ16B8M4CDT_ISO_PHY_ISO_SPARE_2 ro
  [31:0] ISO_SPARE_X — Spare register
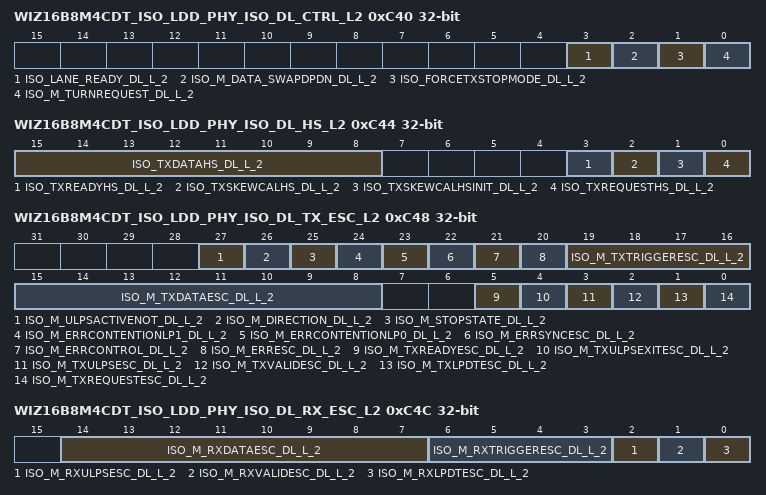
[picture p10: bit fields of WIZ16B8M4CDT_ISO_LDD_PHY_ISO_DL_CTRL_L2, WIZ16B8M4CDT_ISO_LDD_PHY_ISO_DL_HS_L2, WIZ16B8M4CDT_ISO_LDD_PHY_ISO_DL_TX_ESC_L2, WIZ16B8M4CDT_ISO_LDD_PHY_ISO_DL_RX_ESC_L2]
0xC40 WIZ16B8M4CDT_ISO_LDD_PHY_ISO_DL_CTRL_L2 access per field
  [3] ISO_LANE_READY_DL_L_2 ro — High Speed data lane ready lane_ready_dl_l_2
  [2] ISO_M_DATA_SWAPDPDN_DL_L_2 rw — Swaps the tx_p and tx_m differential pins M_Data_SwapDpDn_dl_l_2
  [1] ISO_FORCETXSTOPMODE_DL_L_2 rw — Drives the lane forcing into stop state ForceTxStopMode_dl_l_2
  [0] ISO_M_TURNREQUEST_DL_L_2 rw — Drives the Turnaround request M_TurnRequest_dl_l_2
0xC44 WIZ16B8M4CDT_ISO_LDD_PHY_ISO_DL_HS_L2 access per field
  [15:8] ISO_TXDATAHS_DL_L_2 rw — Drives the high speed transmission data TxDataHS_dl_l_2[7:0]
  [3] ISO_TXREADYHS_DL_L_2 ro — Stores the high speed data transmission ready TxReadyHS_dl_l_2
  [2] ISO_TXSKEWCALHS_DL_L_2 rw — Drives transmission skew calibration periodic TxSkewCalHS_dl_l_2
  [1] ISO_TXSKEWCALHSINIT_DL_L_2 rw — Drives to run the initial skew calibration TxSkewCalHSInit_dl_l_2
  [0] ISO_TXREQUESTHS_DL_L_2 rw — Drives the High Speed Data Transmission Request TxRequestHS_dl_l_2
0xC48 WIZ16B8M4CDT_ISO_LDD_PHY_ISO_DL_TX_ESC_L2 access per field
  [27] ISO_M_ULPSACTIVENOT_DL_L_2 ro — Lane ULPS Active state M_ULPSActiveNot_dl_l_2
  [26] ISO_M_DIRECTION_DL_L_2 ro — Lane transmit / receive direction M_Direction_dl_l_2
  [25] ISO_M_STOPSTATE_DL_L_2 ro — Lane Stop State M_StopState_dl_l_2
  [24] ISO_M_ERRCONTENTIONLP1_DL_L_2 ro — LP1 contention Error M_ErrContentionLP1_dl_l_2
  [23] ISO_M_ERRCONTENTIONLP0_DL_L_2 ro — LP1 contention Error M_ErrContentionLP0_dl_l_2
  [22] ISO_M_ERRSYNCESC_DL_L_2 ro — Low power data transmission sync error M_ErrSyncEsc_dl_l_2
  [21] ISO_M_ERRCONTROL_DL_L_2 ro — Control Error M_ErrControl_dl_l_2
  [20] ISO_M_ERRESC_DL_L_2 ro — Escape Entry Error M_ErrEsc_dl_l_2
  [19:16] ISO_M_TXTRIGGERESC_DL_L_2 rw — Transmit escape mode trigger M_TxTriggerEsc_dl_l_2[3:0]
  [15:8] ISO_M_TXDATAESC_DL_L_2 rw — Transmit escape mode low power transmit data M_TxDataEsc_dl_l_2[7:0]
  [5] ISO_M_TXREADYESC_DL_L_2 ro — Transmit escape mode low power transmit data ready M_TxReadyEsc_dl_l_2
  [4] ISO_M_TXULPSEXITESC_DL_L_2 rw — Initiate exit of ULPS M_TxULPSExitEsc_dl_l_2
  [3] ISO_M_TXULPSESC_DL_L_2 rw — Transmit escape mode ultra low power state M_TxULPSEsc_dl_l_2
  [2] ISO_M_TXVALIDESC_DL_L_2 rw — Transmit escape mode low power transmit data valid M_TxValidEsc_dl_l_2
  [1] ISO_M_TXLPDTESC_DL_L_2 rw — Transmit escape mode low power data M_TxLPDTEsc_dl_l_2
  [0] ISO_M_TXREQUESTESC_DL_L_2 rw — Transmit escape mode request M_TxRequestEsc_dl_l_2
0xC4C WIZ16B8M4CDT_ISO_LDD_PHY_ISO_DL_RX_ESC_L2 ro
  [14:7] ISO_M_RXDATAESC_DL_L_2 — Receive escape mode low power receive data M_RxDataEsc_dl_l_2[7:0]
  [6:3] ISO_M_RXTRIGGERESC_DL_L_2 — Receive escape mode low power trigger state M_RxTriggerEsc_dl_l_2[3:0]
  [2] ISO_M_RXULPSESC_DL_L_2 — Receive escape mode low power ultra low power state M_RxULPSEsc_dl_l_2
  [1] ISO_M_RXVALIDESC_DL_L_2 — Receive escape mode low power receive data M_RxValidEsc_dl_l_2
  [0] ISO_M_RXLPDTESC_DL_L_2 — Receive escape mode low power data M_RxLPDTEsc_dl_l_2
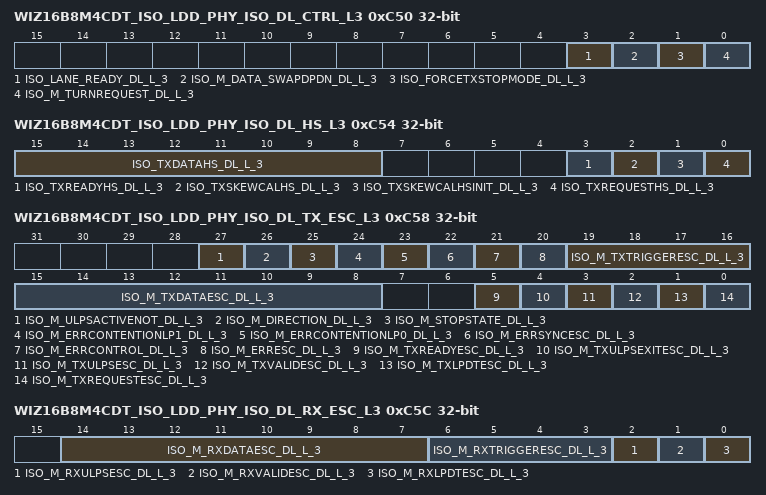
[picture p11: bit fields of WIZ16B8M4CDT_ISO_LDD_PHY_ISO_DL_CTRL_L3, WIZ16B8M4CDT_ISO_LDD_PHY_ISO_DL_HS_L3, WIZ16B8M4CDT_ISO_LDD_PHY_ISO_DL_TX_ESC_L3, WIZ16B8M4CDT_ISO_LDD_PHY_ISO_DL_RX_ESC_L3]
0xC50 WIZ16B8M4CDT_ISO_LDD_PHY_ISO_DL_CTRL_L3 access per field
  [3] ISO_LANE_READY_DL_L_3 ro — High Speed data lane ready lane_ready_dl_l_3
  [2] ISO_M_DATA_SWAPDPDN_DL_L_3 rw — Swaps the tx_p and tx_m differential pins M_Data_SwapDpDn_dl_l_3
  [1] ISO_FORCETXSTOPMODE_DL_L_3 rw — Drives the lane forcing into stop state ForceTxStopMode_dl_l_3
  [0] ISO_M_TURNREQUEST_DL_L_3 rw — Drives the Turnaround request M_TurnRequest_dl_l_3
0xC54 WIZ16B8M4CDT_ISO_LDD_PHY_ISO_DL_HS_L3 access per field
  [15:8] ISO_TXDATAHS_DL_L_3 rw — Drives the high speed transmission data TxDataHS_dl_l_3[7:0]
  [3] ISO_TXREADYHS_DL_L_3 ro — Stores the high speed data transmission ready TxReadyHS_dl_l_3
  [2] ISO_TXSKEWCALHS_DL_L_3 rw — Drives transmission skew calibration periodic TxSkewCalHS_dl_l_3
  [1] ISO_TXSKEWCALHSINIT_DL_L_3 rw — Drives to run the initial skew calibration TxSkewCalHSInit_dl_l_3
  [0] ISO_TXREQUESTHS_DL_L_3 rw — Drives the High Speed Data Transmission Request TxRequestHS_dl_l_3
0xC58 WIZ16B8M4CDT_ISO_LDD_PHY_ISO_DL_TX_ESC_L3 access per field
  [27] ISO_M_ULPSACTIVENOT_DL_L_3 ro — Lane ULPS Active state M_ULPSActiveNot_dl_l_3
  [26] ISO_M_DIRECTION_DL_L_3 ro — Lane transmit / receive direction M_Direction_dl_l_3
  [25] ISO_M_STOPSTATE_DL_L_3 ro — Lane Stop State M_StopState_dl_l_3
  [24] ISO_M_ERRCONTENTIONLP1_DL_L_3 ro — LP1 contention Error M_ErrContentionLP1_dl_l_3
  [23] ISO_M_ERRCONTENTIONLP0_DL_L_3 ro — LP1 contention Error M_ErrContentionLP0_dl_l_3
  [22] ISO_M_ERRSYNCESC_DL_L_3 ro — Low power data transmission sync error M_ErrSyncEsc_dl_l_3
  [21] ISO_M_ERRCONTROL_DL_L_3 ro — Control Error M_ErrControl_dl_l_3
  [20] ISO_M_ERRESC_DL_L_3 ro — Escape Entry Error M_ErrEsc_dl_l_3
  [19:16] ISO_M_TXTRIGGERESC_DL_L_3 rw — Transmit escape mode trigger M_TxTriggerEsc_dl_l_3[3:0]
  [15:8] ISO_M_TXDATAESC_DL_L_3 rw — Transmit escape mode low power transmit data M_TxDataEsc_dl_l_3[7:0]
  [5] ISO_M_TXREADYESC_DL_L_3 ro — Transmit escape mode low power transmit data ready M_TxReadyEsc_dl_l_3
  [4] ISO_M_TXULPSEXITESC_DL_L_3 rw — Initiate exit of ULPS M_TxULPSExitEsc_dl_l_3
  [3] ISO_M_TXULPSESC_DL_L_3 rw — Transmit escape mode ultra low power state M_TxULPSEsc_dl_l_3
  [2] ISO_M_TXVALIDESC_DL_L_3 rw — Transmit escape mode low power transmit data valid M_TxValidEsc_dl_l_3
  [1] ISO_M_TXLPDTESC_DL_L_3 rw — Transmit escape mode low power data M_TxLPDTEsc_dl_l_3
  [0] ISO_M_TXREQUESTESC_DL_L_3 rw — Transmit escape mode request M_TxRequestEsc_dl_l_3
0xC5C WIZ16B8M4CDT_ISO_LDD_PHY_ISO_DL_RX_ESC_L3 ro
  [14:7] ISO_M_RXDATAESC_DL_L_3 — Receive escape mode low power receive data M_RxDataEsc_dl_l_3[7:0]
  [6:3] ISO_M_RXTRIGGERESC_DL_L_3 — Receive escape mode low power trigger state M_RxTriggerEsc_dl_l_3[3:0]
  [2] ISO_M_RXULPSESC_DL_L_3 — Receive escape mode low power ultra low power state M_RxULPSEsc_dl_l_3
  [1] ISO_M_RXVALIDESC_DL_L_3 — Receive escape mode low power receive data M_RxValidEsc_dl_l_3
  [0] ISO_M_RXLPDTESC_DL_L_3 — Receive escape mode low power data M_RxLPDTEsc_dl_l_3
